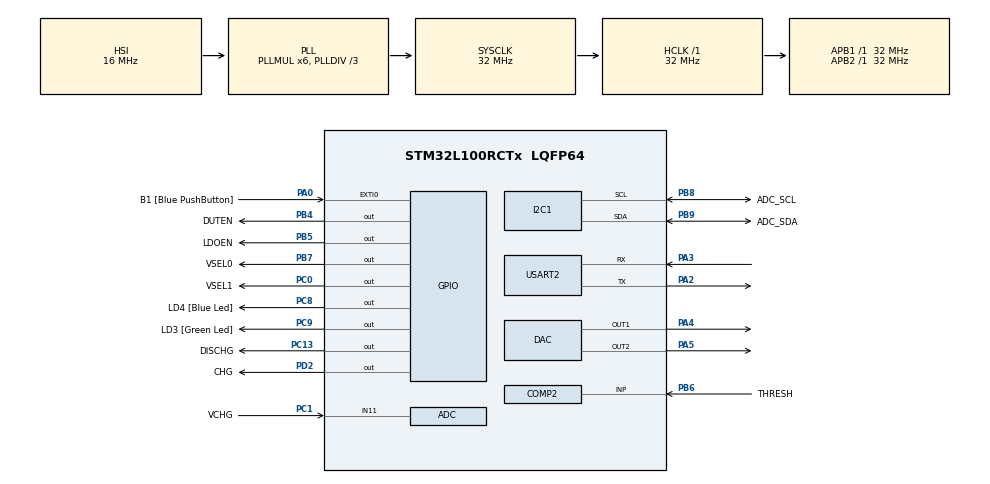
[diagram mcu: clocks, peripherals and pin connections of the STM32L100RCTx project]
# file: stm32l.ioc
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Mcu.Family=STM32L1
PH0-OSC_IN.Signal=RCC_OSC_IN
NVIC.I2C1_EV_IRQn=true\:5\:0\:false\:false\:true\:true\:true\:true
Dma.ADC.0.Mode=DMA_CIRCULAR
ADC.Rank-0\#ChannelRegularConversion=1
PA14.GPIO_Label=SWCLK
Dma.ADC.0.Priority=DMA_PRIORITY_LOW
PC0.GPIO_Label=VSEL1
ADC.ScanConvMode=ADC_SCAN_ENABLE
Dma.I2C1_RX.2.MemDataAlignment=DMA_MDATAALIGN_BYTE
PB6.GPIO_Label=THRESH
PC15-OSC32_OUT.GPIO_Label=PC15-OSC32_OUT
Dma.USART2_RX.1.MemDataAlignment=DMA_MDATAALIGN_BYTE
RCC.SYSCLKSource=RCC_SYSCLKSOURCE_PLLCLK
ProjectManager.StackSize=0x400
SH.COMP_DAC2_group.0=DAC_OUT2,DAC_OUT2
VP_FREERTOS_VS_CMSIS_V2.Mode=CMSIS_V2
ADC.NbrOfConversion=2
RCC.PLLDIV=RCC_PLL_DIV3
NVIC.ADC1_IRQn=true\:5\:0\:false\:false\:true\:true\:true\:true
Dma.I2C1_RX.2.PeriphDataAlignment=DMA_PDATAALIGN_BYTE
Dma.ADC.0.PeriphInc=DMA_PINC_DISABLE
RCC.HCLKFreq_Value=32000000
PC13-WKUP2.GPIO_Label=DISCHG
RCC.APB2TimFreq_Value=32000000
PB6.Signal=COMP2_INP
PB6.Mode=INP
Dma.USART2_RX.1.PeriphInc=DMA_PINC_DISABLE
Dma.USART2_RX.1.MemInc=DMA_MINC_ENABLE
RCC.AHBFreq_Value=32000000
PH0-OSC_IN.Mode=HSE-External-Oscillator
PH0-OSC_IN.GPIO_Label=PH0-OSC_IN
Dma.ADC.0.Direction=DMA_PERIPH_TO_MEMORY
RCC.HSE_VALUE=8000000
PC13-WKUP2.Signal=GPIO_Output
RCC.PLLMUL=RCC_PLL_MUL6
Dma.I2C1_RX.2.Mode=DMA_NORMAL
RCC.RTCClockSelectionVirtual=RCC_RTCCLKSOURCE_LSE
PB7.Signal=GPIO_Output
TIM6.Period=39999
Dma.I2C1_RX.2.Priority=DMA_PRIORITY_LOW
NVIC.I2C1_ER_IRQn=true\:5\:0\:false\:false\:true\:true\:true\:true
Dma.ADC.0.MemInc=DMA_MINC_ENABLE
PH1-OSC_OUT.Mode=HSE-External-Oscillator
PB7.GPIO_Label=VSEL0
Mcu.Package=LQFP64
PB9.Signal=I2C1_SDA
NVIC.TimeBase=TIM3_IRQn
Dma.I2C1_RX.2.PeriphInc=DMA_PINC_DISABLE
USART2.VirtualMode=VM_ASYNC
RCC.USBOutput=48000000
Dma.I2C1_RX.2.Instance=DMA1_Channel7
Dma.ADC.0.Instance=DMA1_Channel1
COMP2.Mode=COMP_MODE_HIGHSPEED
NVIC.TimeBaseIP=TIM3
ADC.Channel-0\#ChannelRegularConversion=ADC_CHANNEL_11
Dma.I2C1_RX.2.MemInc=DMA_MINC_ENABLE
Dma.ADC.0.MemDataAlignment=DMA_MDATAALIGN_HALFWORD
PB5.GPIO_Label=LDOEN
Dma.Request2=I2C1_RX
Dma.Request1=USART2_RX
RCC.APB1TimFreq_Value=32000000
PC14-OSC32_IN.GPIO_Label=PC14-OSC32_IN
ADC.SamplingTime-1\#ChannelRegularConversion=ADC_SAMPLETIME_192CYCLES
Dma.USART2_RX.1.Mode=DMA_CIRCULAR
Dma.Request0=ADC
ADC.ExternalTrigConv=ADC_EXTERNALTRIGCONV_T6_TRGO
PB4.Signal=GPIO_Output
PA3.Signal=USART2_RX
PB3.GPIO_Label=SWO
RCC.MSI_VALUE=2097000
SH.COMP_DAC1_group.0=DAC_OUT1,DAC_OUT1
NVIC.DMA1_Channel6_IRQn=true\:5\:0\:false\:false\:true\:true\:false\:true
Dma.USART2_RX.1.Priority=DMA_PRIORITY_LOW
FREERTOS.Tasks01=defaultTask,24,128,StartDefaultTask,Default,NULL,Dynamic,NULL,NULL
PB9.GPIO_Label=ADC_SDA
PC9.GPIO_Label=LD3 [Green Led]
ADC.Channel-1\#ChannelRegularConversion=ADC_CHANNEL_VREFINT
VP_ADC_Vref_Input.Mode=IN-Vrefint
PC8.Signal=GPIO_Output
TIM6.Prescaler=15
PA0-WKUP1.GPIO_ModeDefaultEXTI=GPIO_MODE_EVT_RISING
VP_TIM6_VS_ClockSourceINT.Mode=Enable_Timer
PC0.Signal=GPIO_Output
PC14-OSC32_IN.Signal=RCC_OSC32_IN
ADC.ClockPrescaler=ADC_CLOCK_ASYNC_DIV4
COMP2.InvertingInput=COMP_INVERTINGINPUT_VREFINT
NVIC.USART2_IRQn=true\:5\:0\:false\:false\:true\:true\:true\:true
Dma.ADC.0.PeriphDataAlignment=DMA_PDATAALIGN_HALFWORD
PC8.GPIO_Label=LD4 [Blue Led]
PA3.Mode=Asynchronous
PA13.Signal=SYS_JTMS-SWDIO
TIM6.AutoReloadPreload=TIM_AUTORELOAD_PRELOAD_ENABLE
PB8.GPIO_Label=ADC_SCL
VP_SYS_VS_tim3.Mode=TIM3
ProjectManager.TargetToolchain=Makefile
ADC.Rank-1\#ChannelRegularConversion=2
PB9.Mode=I2C
PA0-WKUP1.Signal=GPXTI0
ADC.NbrOfConversionFlag=1
RCC.LSE_VALUE=32768
PC15-OSC32_OUT.Signal=RCC_OSC32_OUT
Dma.USART2_RX.1.Instance=DMA1_Channel6
Dma.USART2_RX.1.Direction=DMA_PERIPH_TO_MEMORY
PA5.Signal=COMP_DAC2_group
ADC.DMAContinuousRequests=ENABLE
Dma.USART2_RX.1.PeriphDataAlignment=DMA_PDATAALIGN_BYTE
board=STM32L100C-DISCO
RCC.VCOOutputFreq_Value=96000000
RCC.LSEState=RCC_LSE_ON
NVIC.TIM3_IRQn=true\:0\:0\:false\:false\:true\:false\:false\:true
RCC.APB2Freq_Value=32000000
PB4.GPIO_Label=DUTEN
NVIC.COMP_IRQn=true\:5\:0\:false\:false\:true\:true\:false\:true
PC1.GPIO_Label=VCHG
TIM6.TIM_MasterOutputTrigger=TIM_TRGO_UPDATE
PH1-OSC_OUT.Signal=RCC_OSC_OUT
PH1-OSC_OUT.GPIO_Label=PH1-OSC_OUT
Mcu.Name=STM32L100RCTx
PA2.Signal=USART2_TX
PA13.GPIO_Label=SWDIO
RCC.48MHZClocksFreq_Value=48000000
PB3.Signal=SYS_JTDO-TRACESWO
PA4.Signal=COMP_DAC1_group
RCC.SYSCLKFreq_VALUE=32000000
PB5.Signal=GPIO_Output
PA14.Signal=SYS_JTCK-SWCLK
PA0-WKUP1.GPIO_Label=B1 [Blue PushButton]
ProjectManager.HeapSize=0x200
RCC.HSI_VALUE=16000000
NVIC.PriorityGroup=NVIC_PRIORITYGROUP_4
PB8.Mode=I2C
PA2.Mode=Asynchronous
PB8.Signal=I2C1_SCL
ADC.SamplingTime-0\#ChannelRegularConversion=ADC_SAMPLETIME_192CYCLES
NVIC.DMA1_Channel7_IRQn=true\:5\:0\:false\:false\:true\:true\:false\:true
PC9.Signal=GPIO_Output
COMP2.TriggerMode=COMP_TRIGGERMODE_IT_FALLING
NVIC.DMA1_Channel1_IRQn=true\:5\:0\:false\:false\:true\:true\:false\:true
PD2.Signal=GPIO_Output
RCC.APB1Freq_Value=32000000
ADC.ContinuousConvMode=DISABLE
VP_COMP2_VS_VREFINT.Mode=VREFINT
PC1.Signal=ADC_IN11
PD2.GPIO_Label=CHG
PC1.Mode=IN11
Dma.I2C1_RX.2.Direction=DMA_PERIPH_TO_MEMORY

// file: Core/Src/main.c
/* USER CODE BEGIN Header */
/**
  ******************************************************************************
  * @file           : main.c
  * @brief          : Main program body
  ******************************************************************************
  * @attention
  *
  * <h2><center>&copy; Copyright (c) 2021 STMicroelectronics.
  * All rights reserved.</center></h2>
  *
  * This software component is licensed by ST under BSD 3-Clause license,
  * the "License"; You may not use this file except in compliance with the
  * License. You may obtain a copy of the License at:
  *                        opensource.org/licenses/BSD-3-Clause
  *
  ******************************************************************************
  */
/* USER CODE END Header */
#include "main.h"
#include "cmsis_os.h"

/* USER CODE BEGIN Includes */
#include "app.h"
#include "debug.h"
/* USER CODE END Includes */

ADC_HandleTypeDef hadc;
DMA_HandleTypeDef hdma_adc;

COMP_HandleTypeDef hcomp2;

DAC_HandleTypeDef hdac;

I2C_HandleTypeDef hi2c1;
DMA_HandleTypeDef hdma_i2c1_rx;

TIM_HandleTypeDef htim6;

UART_HandleTypeDef huart2;
DMA_HandleTypeDef hdma_usart2_rx;

/* Definitions for defaultTask */
osThreadId_t defaultTaskHandle;
const osThreadAttr_t defaultTask_attributes = {
  .name = "defaultTask",
  .priority = (osPriority_t) osPriorityNormal,
  .stack_size = 128 * 4
};

void SystemClock_Config(void);
static void MX_GPIO_Init(void);
static void MX_DMA_Init(void);
static void MX_COMP2_Init(void);
static void MX_DAC_Init(void);
static void MX_USART2_UART_Init(void);
static void MX_ADC_Init(void);
static void MX_I2C1_Init(void);
static void MX_TIM6_Init(void);
void StartDefaultTask(void *argument);

int main(void)
{

  /* MCU Configuration--------------------------------------------------------*/

  /* Reset of all peripherals, Initializes the Flash interface and the Systick. */
  HAL_Init();

  /* Configure the system clock */
  SystemClock_Config();

  /* Initialize all configured peripherals */
  MX_GPIO_Init();
  MX_DMA_Init();
  MX_COMP2_Init();
  MX_DAC_Init();
  MX_USART2_UART_Init();
  MX_ADC_Init();
  MX_I2C1_Init();
  MX_TIM6_Init();
  /* USER CODE BEGIN 2 */

  app_init();
  /* USER CODE END 2 */

  /* Init scheduler */
  osKernelInitialize();

  /* Create the thread(s) */
  /* creation of defaultTask */
  defaultTaskHandle = osThreadNew(StartDefaultTask, NULL, &defaultTask_attributes);

  /* Start scheduler */
  osKernelStart();

  /* We should never get here as control is now taken by the scheduler */
  /* Infinite loop */
  while (1)
  {

    /* USER CODE BEGIN 3 */
    app_run();
  }
  /* USER CODE END 3 */
}

void SystemClock_Config(void)
{
  RCC_OscInitTypeDef RCC_OscInitStruct = {0};
  RCC_ClkInitTypeDef RCC_ClkInitStruct = {0};

  /** Configure the main internal regulator output voltage
  */
  __HAL_PWR_VOLTAGESCALING_CONFIG(PWR_REGULATOR_VOLTAGE_SCALE1);
  /** Initializes the RCC Oscillators according to the specified parameters
  * in the RCC_OscInitTypeDef structure.
  */
  RCC_OscInitStruct.OscillatorType = RCC_OSCILLATORTYPE_HSI;
  RCC_OscInitStruct.HSIState = RCC_HSI_ON;
  RCC_OscInitStruct.HSICalibrationValue = RCC_HSICALIBRATION_DEFAULT;
  RCC_OscInitStruct.PLL.PLLState = RCC_PLL_ON;
  RCC_OscInitStruct.PLL.PLLSource = RCC_PLLSOURCE_HSI;
  RCC_OscInitStruct.PLL.PLLMUL = RCC_PLL_MUL6;
  RCC_OscInitStruct.PLL.PLLDIV = RCC_PLL_DIV3;
  if (HAL_RCC_OscConfig(&RCC_OscInitStruct) != HAL_OK)
  {
    Error_Handler();
  }
  /** Initializes the CPU, AHB and APB buses clocks
  */
  RCC_ClkInitStruct.ClockType = RCC_CLOCKTYPE_HCLK|RCC_CLOCKTYPE_SYSCLK
                              |RCC_CLOCKTYPE_PCLK1|RCC_CLOCKTYPE_PCLK2;
  RCC_ClkInitStruct.SYSCLKSource = RCC_SYSCLKSOURCE_PLLCLK;
  RCC_ClkInitStruct.AHBCLKDivider = RCC_SYSCLK_DIV1;
  RCC_ClkInitStruct.APB1CLKDivider = RCC_HCLK_DIV1;
  RCC_ClkInitStruct.APB2CLKDivider = RCC_HCLK_DIV1;

  if (HAL_RCC_ClockConfig(&RCC_ClkInitStruct, FLASH_LATENCY_1) != HAL_OK)
  {
    Error_Handler();
  }
}

static void MX_ADC_Init(void)
{

  ADC_ChannelConfTypeDef sConfig = {0};

  /** Configure the global features of the ADC (Clock, Resolution, Data Alignment and number of conversion)
  */
  hadc.Instance = ADC1;
  hadc.Init.ClockPrescaler = ADC_CLOCK_ASYNC_DIV4;
  hadc.Init.Resolution = ADC_RESOLUTION_12B;
  hadc.Init.DataAlign = ADC_DATAALIGN_RIGHT;
  hadc.Init.ScanConvMode = ADC_SCAN_ENABLE;
  hadc.Init.EOCSelection = ADC_EOC_SEQ_CONV;
  hadc.Init.LowPowerAutoWait = ADC_AUTOWAIT_DISABLE;
  hadc.Init.LowPowerAutoPowerOff = ADC_AUTOPOWEROFF_DISABLE;
  hadc.Init.ChannelsBank = ADC_CHANNELS_BANK_A;
  hadc.Init.ContinuousConvMode = DISABLE;
  hadc.Init.NbrOfConversion = 2;
  hadc.Init.DiscontinuousConvMode = DISABLE;
  hadc.Init.ExternalTrigConv = ADC_EXTERNALTRIGCONV_T6_TRGO;
  hadc.Init.ExternalTrigConvEdge = ADC_EXTERNALTRIGCONVEDGE_RISING;
  hadc.Init.DMAContinuousRequests = ENABLE;
  if (HAL_ADC_Init(&hadc) != HAL_OK)
  {
    Error_Handler();
  }
  /** Configure for the selected ADC regular channel its corresponding rank in the sequencer and its sample time.
  */
  sConfig.Channel = ADC_CHANNEL_11;
  sConfig.Rank = ADC_REGULAR_RANK_1;
  sConfig.SamplingTime = ADC_SAMPLETIME_192CYCLES;
  if (HAL_ADC_ConfigChannel(&hadc, &sConfig) != HAL_OK)
  {
    Error_Handler();
  }
  /** Configure for the selected ADC regular channel its corresponding rank in the sequencer and its sample time.
  */
  sConfig.Channel = ADC_CHANNEL_VREFINT;
  sConfig.Rank = ADC_REGULAR_RANK_2;
  if (HAL_ADC_ConfigChannel(&hadc, &sConfig) != HAL_OK)
  {
    Error_Handler();
  }

}

static void MX_COMP2_Init(void)
{

  hcomp2.Instance = COMP2;
  hcomp2.Init.InvertingInput = COMP_INVERTINGINPUT_VREFINT;
  hcomp2.Init.NonInvertingInput = COMP_NONINVERTINGINPUT_PB6;
  hcomp2.Init.Output = COMP_OUTPUT_NONE;
  hcomp2.Init.Mode = COMP_MODE_HIGHSPEED;
  hcomp2.Init.WindowMode = COMP_WINDOWMODE_DISABLE;
  hcomp2.Init.TriggerMode = COMP_TRIGGERMODE_IT_FALLING;
  if (HAL_COMP_Init(&hcomp2) != HAL_OK)
  {
    Error_Handler();
  }

}

static void MX_DAC_Init(void)
{

  DAC_ChannelConfTypeDef sConfig = {0};

  /** DAC Initialization
  */
  hdac.Instance = DAC;
  if (HAL_DAC_Init(&hdac) != HAL_OK)
  {
    Error_Handler();
  }
  /** DAC channel OUT1 config
  */
  sConfig.DAC_Trigger = DAC_TRIGGER_NONE;
  sConfig.DAC_OutputBuffer = DAC_OUTPUTBUFFER_ENABLE;
  if (HAL_DAC_ConfigChannel(&hdac, &sConfig, DAC_CHANNEL_1) != HAL_OK)
  {
    Error_Handler();
  }
  /** DAC channel OUT2 config
  */
  if (HAL_DAC_ConfigChannel(&hdac, &sConfig, DAC_CHANNEL_2) != HAL_OK)
  {
    Error_Handler();
  }

}

static void MX_I2C1_Init(void)
{

  hi2c1.Instance = I2C1;
  hi2c1.Init.ClockSpeed = 100000;
  hi2c1.Init.DutyCycle = I2C_DUTYCYCLE_2;
  hi2c1.Init.OwnAddress1 = 0;
  hi2c1.Init.AddressingMode = I2C_ADDRESSINGMODE_7BIT;
  hi2c1.Init.DualAddressMode = I2C_DUALADDRESS_DISABLE;
  hi2c1.Init.OwnAddress2 = 0;
  hi2c1.Init.GeneralCallMode = I2C_GENERALCALL_DISABLE;
  hi2c1.Init.NoStretchMode = I2C_NOSTRETCH_DISABLE;
  if (HAL_I2C_Init(&hi2c1) != HAL_OK)
  {
    Error_Handler();
  }

}

static void MX_TIM6_Init(void)
{

  TIM_MasterConfigTypeDef sMasterConfig = {0};

  htim6.Instance = TIM6;
  htim6.Init.Prescaler = 15;
  htim6.Init.CounterMode = TIM_COUNTERMODE_UP;
  htim6.Init.Period = 39999;
  htim6.Init.AutoReloadPreload = TIM_AUTORELOAD_PRELOAD_ENABLE;
  if (HAL_TIM_Base_Init(&htim6) != HAL_OK)
  {
    Error_Handler();
  }
  sMasterConfig.MasterOutputTrigger = TIM_TRGO_UPDATE;
  sMasterConfig.MasterSlaveMode = TIM_MASTERSLAVEMODE_DISABLE;
  if (HAL_TIMEx_MasterConfigSynchronization(&htim6, &sMasterConfig) != HAL_OK)
  {
    Error_Handler();
  }

}

static void MX_USART2_UART_Init(void)
{

  huart2.Instance = USART2;
  huart2.Init.BaudRate = 115200;
  huart2.Init.WordLength = UART_WORDLENGTH_8B;
  huart2.Init.StopBits = UART_STOPBITS_1;
  huart2.Init.Parity = UART_PARITY_NONE;
  huart2.Init.Mode = UART_MODE_TX_RX;
  huart2.Init.HwFlowCtl = UART_HWCONTROL_NONE;
  huart2.Init.OverSampling = UART_OVERSAMPLING_16;
  if (HAL_UART_Init(&huart2) != HAL_OK)
  {
    Error_Handler();
  }

}

static void MX_DMA_Init(void)
{

  /* DMA controller clock enable */
  __HAL_RCC_DMA1_CLK_ENABLE();

  /* DMA interrupt init */
  /* DMA1_Channel1_IRQn interrupt configuration */
  HAL_NVIC_SetPriority(DMA1_Channel1_IRQn, 5, 0);
  HAL_NVIC_EnableIRQ(DMA1_Channel1_IRQn);
  /* DMA1_Channel6_IRQn interrupt configuration */
  HAL_NVIC_SetPriority(DMA1_Channel6_IRQn, 5, 0);
  HAL_NVIC_EnableIRQ(DMA1_Channel6_IRQn);
  /* DMA1_Channel7_IRQn interrupt configuration */
  HAL_NVIC_SetPriority(DMA1_Channel7_IRQn, 5, 0);
  HAL_NVIC_EnableIRQ(DMA1_Channel7_IRQn);

}

static void MX_GPIO_Init(void)
{
  GPIO_InitTypeDef GPIO_InitStruct = {0};

  /* GPIO Ports Clock Enable */
  __HAL_RCC_GPIOC_CLK_ENABLE();
  __HAL_RCC_GPIOH_CLK_ENABLE();
  __HAL_RCC_GPIOA_CLK_ENABLE();
  __HAL_RCC_GPIOD_CLK_ENABLE();
  __HAL_RCC_GPIOB_CLK_ENABLE();

  /*Configure GPIO pin Output Level */
  HAL_GPIO_WritePin(GPIOC, DISCHG_Pin|VSEL1_Pin|LD4_Pin|LD3_Pin, GPIO_PIN_RESET);

  /*Configure GPIO pin Output Level */
  HAL_GPIO_WritePin(CHG_GPIO_Port, CHG_Pin, GPIO_PIN_RESET);

  /*Configure GPIO pin Output Level */
  HAL_GPIO_WritePin(GPIOB, DUTEN_Pin|LDOEN_Pin|VSEL0_Pin, GPIO_PIN_RESET);

  /*Configure GPIO pins : DISCHG_Pin VSEL1_Pin LD4_Pin LD3_Pin */
  GPIO_InitStruct.Pin = DISCHG_Pin|VSEL1_Pin|LD4_Pin|LD3_Pin;
  GPIO_InitStruct.Mode = GPIO_MODE_OUTPUT_PP;
  GPIO_InitStruct.Pull = GPIO_NOPULL;
  GPIO_InitStruct.Speed = GPIO_SPEED_FREQ_LOW;
  HAL_GPIO_Init(GPIOC, &GPIO_InitStruct);

  /*Configure GPIO pin : B1_Pin */
  GPIO_InitStruct.Pin = B1_Pin;
  GPIO_InitStruct.Mode = GPIO_MODE_EVT_RISING;
  GPIO_InitStruct.Pull = GPIO_NOPULL;
  HAL_GPIO_Init(B1_GPIO_Port, &GPIO_InitStruct);

  /*Configure GPIO pin : CHG_Pin */
  GPIO_InitStruct.Pin = CHG_Pin;
  GPIO_InitStruct.Mode = GPIO_MODE_OUTPUT_PP;
  GPIO_InitStruct.Pull = GPIO_NOPULL;
  GPIO_InitStruct.Speed = GPIO_SPEED_FREQ_LOW;
  HAL_GPIO_Init(CHG_GPIO_Port, &GPIO_InitStruct);

  /*Configure GPIO pins : DUTEN_Pin LDOEN_Pin VSEL0_Pin */
  GPIO_InitStruct.Pin = DUTEN_Pin|LDOEN_Pin|VSEL0_Pin;
  GPIO_InitStruct.Mode = GPIO_MODE_OUTPUT_PP;
  GPIO_InitStruct.Pull = GPIO_NOPULL;
  GPIO_InitStruct.Speed = GPIO_SPEED_FREQ_LOW;
  HAL_GPIO_Init(GPIOB, &GPIO_InitStruct);

}

void StartDefaultTask(void *argument)
{
  for(;;)
  {
    osDelay(1);
  }
}

 /**
  * @brief  Period elapsed callback in non blocking mode
  * @note   This function is called  when TIM3 interrupt took place, inside
  * HAL_TIM_IRQHandler(). It makes a direct call to HAL_IncTick() to increment
  * a global variable "uwTick" used as application time base.
  * @param  htim : TIM handle
  * @retval None
  */
void HAL_TIM_PeriodElapsedCallback(TIM_HandleTypeDef *htim)
{
  if (htim->Instance == TIM3) {
    HAL_IncTick();
  }
}

void Error_Handler(void)
{
  /* USER CODE BEGIN Error_Handler_Debug */
  /* User can add his own implementation to report the HAL error return state */
  __disable_irq();
  while (1)
  {
      dbgprintf("Error handler\r\n");
  }
  /* USER CODE END Error_Handler_Debug */
}

/************************ (C) COPYRIGHT STMicroelectronics *****END OF FILE****/
